# 3066H register map
File version: 1.0
Registers are 32-bit, access per field, reset 0x0 unless marked. A register's access mark holds for its fields unless they carry their own. Offsets are from the block's base; [hi:lo] are bit positions; {n}, {i} and the like mark numbered series.

## DMA0 — DMA0 peripheral interface
Base 0x1C000000
Same registers: DMA1 0x1C001000
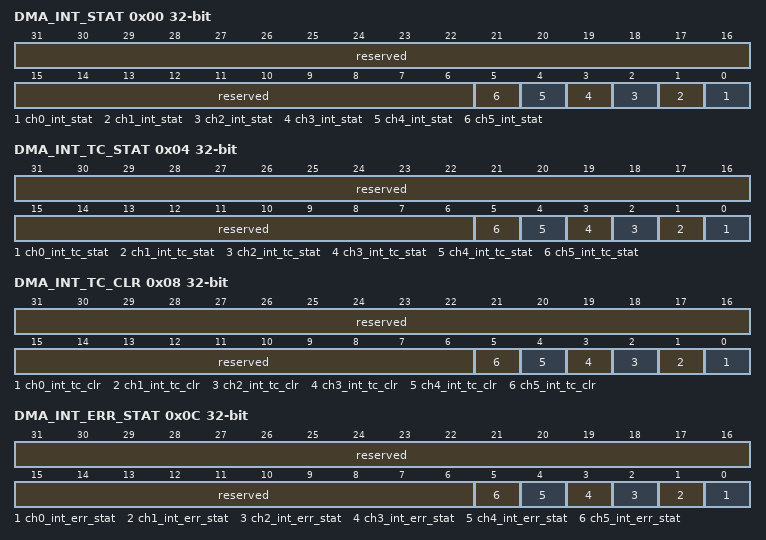
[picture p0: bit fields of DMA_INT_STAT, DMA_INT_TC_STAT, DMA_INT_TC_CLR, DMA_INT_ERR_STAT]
0x00 DMA_INT_STAT ro — DMA_INT_STAT为DMA中断状态寄存器。
  [31:6] reserved — 保留。
  [n] ch{n}_int_stat (n=0..5) — 通道{n}经屏蔽后的中断状态。 0：未产生中断； 1：已产生中断（传输错误或传输完成）。
0x04 DMA_INT_TC_STAT ro — DMA_INT_TC_STAT为DMA传输完成中断状态寄存器。
  [31:6] reserved — 保留。
  [n] ch{n}_int_tc_stat (n=0..5) — 通道{n}经屏蔽后的传输完成中断状态。 0：未产生中断； 1：已产生中断。
0x08 DMA_INT_TC_CLR — DMA_INT_TC_CLR为DMA传输完成中断清除寄存器。
  [31:6] reserved ro — 保留。
  [n] ch{n}_int_tc_clr wo (n=0..5) — 清除通道{n}传输完成中断。 0：不清除； 1：清除。
0x0C DMA_INT_ERR_STAT ro — DMA_INT_ERR_STAT为DMA错误中断状态寄存器。
  [31:6] reserved — 保留。
  [n] ch{n}_int_err_stat (n=0..5) — 通道{n}经屏蔽后的错误中断状态。 0：未产生中断； 1：已产生中断。
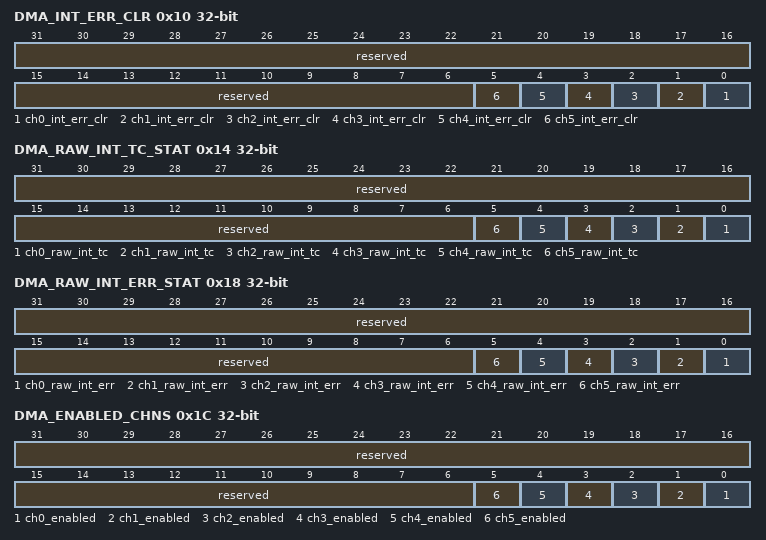
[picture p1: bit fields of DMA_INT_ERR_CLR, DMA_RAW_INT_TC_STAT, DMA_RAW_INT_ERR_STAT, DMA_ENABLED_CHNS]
0x10 DMA_INT_ERR_CLR — DMA_INT_ERR_CLR为DMA错误中断清除寄存器。
  [31:6] reserved ro — 保留。
  [n] ch{n}_int_err_clr wo (n=0..5) — 清除通道{n}错误中断。 0：不清除； 1：清除。
0x14 DMA_RAW_INT_TC_STAT ro — DMA_RAW_INT_TC_STAT为DMA原始传输完成中断寄存器。
  [31:6] reserved — 保留。
  [n] ch{n}_raw_int_tc (n=0..5) — 通道{n}原始传输完成中断状态。 0：未产生传输完成中断； 1：产生传输完成中断。
0x18 DMA_RAW_INT_ERR_STAT ro — DMA_RAW_INT_ERR_STAT为DMA原始错误中断寄存器。
  [31:6] reserved — 保留。
  [n] ch{n}_raw_int_err (n=0..5) — 通道{n}原始错误中断状态。 0：未产生错误中断； 1：产生错误中断。
0x1C DMA_ENABLED_CHNS ro — DMA_ENABLED_CHNS为DMA通道使能状态寄存器。
  [31:6] reserved — 保留。
  [n] ch{n}_enabled (n=0..5) — 通道{n}使能状态。 0：禁止； 1：使能。
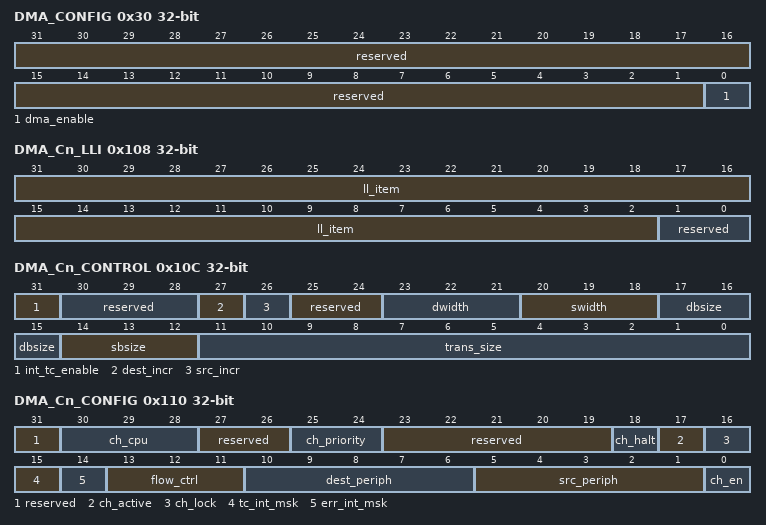
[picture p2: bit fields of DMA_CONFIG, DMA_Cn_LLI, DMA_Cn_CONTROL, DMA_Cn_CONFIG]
0x30 DMA_CONFIG — DMA_CONFIG为DMA配置寄存器。
  [31:1] reserved ro — 保留。
  [0] dma_enable rw — DMA控制器使能。 0：禁止DMA控制器； 1：使能DMA控制器。
0x34 DMA_SYNC rw — DMA_SYNC为DMA请求线同步使能寄存器。
  [31:0] dma_sync_disable — 控制是否需要对请求线进行同步，每bit对应请求请参见“11.3.2.2 外设请求线（SREQ、BREQ和外设流控请求线）”章节。 0：使能对应外设的DMA请求信号同步逻辑； 1：禁止对应外设的DMA请求信号同步逻辑。
0x100 DMA_Cn_SRC_ADDR rw — DMA_Cn_SRC_ADDR为DMA通道n（n=0，1，2，3，4，5）源地址寄存器。寄存器的偏移地址为0x100+n*0x20。其中n的取值为0～5，分别对应DMA通道0～5。每个寄存器在对应的通道被启动前都要由软件对其直接编程。当通道被启动后，该寄存器在下列情况下更新：当源地址递增时。当传完一个完整的数据块后，从链表节点中载入时。当该通道处于活动状态时，读该寄存器得不到有效信息。这是因为当软件得到读出的寄存器值，该寄存器的值已经随着通道传输改变了。对该寄存器的读操作一般是用在通道停止传输的时候，此时读取值显示的是DMA读最后一项时的源地址。
  [31:0] src_addr — DMA源地址。
0x104 DMA_Cn_DEST_ADDR rw — DMA_Cn_DEST_ADDR为DMA通道n（n=0，1，2，3，4，5）目的地址寄存器。偏移地址为：0x104+n*0x20。其中，n的取值为0～5，分别对应DMA通道0～5。通道目的地址寄存器DMA_Cn_DEST_ADDR包含了当前待传数据的目的地址。每个寄存器在对应的通道被启动前，都要由软件对其直接编程。当通道被启动后，该寄存器在下列情况下更新：目的地址递增。传完一个完整的数据块后，从链表节点中载入。当该通道处于活动状态时，读该寄存器得不到有效信息。这是因为当软件得到读出的寄存器值，该寄存器的值已经随着通道传输改变了。在通道停止传输时，读该寄存器，此时读取值显示的是DMA写最后一项时的目的地址。
  [31:0] dest_addr — DMA目的地址。
0x108 DMA_Cn_LLI — DMA_Cn_LLI为DMA通道n（n=0，1，2，3，4，5）链表信息寄存器。偏移地址为：0x108。其中，n的取值为0～5，分别对应DMA通道0～DMA通道5。详细内容请参见“11.3.4 DMA链表”章节。
  [31:2] ll_item rw — 下一个链表节点地址的[31:2]位，地址位[1:0]为0。要求链表地址4Byte对齐。
  [1:0] reserved ro — 保留，写入时必须写0，读出时应屏蔽该位。
0x10C DMA_Cn_CONTROL — DMA_Cn_CONTROL为DMA通道n（n=0，1，2，3，4，5）控制寄存器。偏移地址为：0x10C。其中，n的取值为0～5，分别对应DMA通道0～DMA通道5。
  [31] int_tc_enable rw — 传输完成中断使能位。该位用于决定当前链表节点是否触发传输完成中断。 0：当前链表节点不触发传输完成中断； 1：当前链表节点触发传输完成中断。
  [30:28] reserved ro — 保留。
  [27] dest_incr rw — 目的地址递增。 0：目的地址不递增； 1：目的地址每传一个数就递增一次。 目的设备为外设时目的地址不递增；目的设备为存储器时目的地址递增。
  [26] src_incr rw — 源地址递增。 0：源地址不递增； 1：源地址每传一个数就递增一次。 源设备为外设时源地址不递增；源设备为存储器时源地址递增。
  [25:24] reserved ro — 保留。
  [23:21] dwidth rw — 目的设备传输位宽。 宽于Master位宽的传输位宽是非法的。 目的设备和源设备的位宽可以不一样，硬件自动对数据进行pack和unpack。 dwidth的值和具体的位宽对应关系如表11-5所示。
  [20:18] swidth rw — 源设备传输位宽。 宽于Master位宽的传输位宽是非法的。 目的设备和源设备的位宽可以不一样，硬件自动对数据进行pack和unpack。 swidth的值和具体的位宽对应关系如表11-5所示。
  [17:15] dbsize rw — 目的设备burst长度。 表示目的设备请求1次burst传输（BREQ），DMA向目的地址（固定或递增地址）写数据的个数。 若目的设备是外设，内部有FIFO，burst长度不能超过其FIFO深度，建议配合FIFO水线使用。 若目的设备是外设，内部无FIFO，若配置了目的地址递增，则burst长度不能超过外设的地址空间。否则，递增的目的地址会超过该设备的地址空间，若该地址无映射，那么可能导致无法预料的结果。 若目的设备是存储器，若配置了目的地址递增，则burst长度的配置需要考虑存储器地址边界。目的地址+burst长度不能超过其存储器地址边界。否则，目的地址递增会访问到超过该设备的地址空间，若该地址无映射，那么可能导致无法预料的结果。 若目的设备只支持BREQ，不支持SREQ。目前设备dbsize的配置有限制。目的设备dbsize * dwidth的整数倍须等于trans_size * swidth。 dbsize的值和具体的传输长度的对应关系如表11-4所示。
  [14:12] sbsize rw — 源设备burst长度。 表示源设备请求1次burst传输（BREQ），DMA从源地址（固定或递增地址）读数据的个数。 若源设备是外设，内部有FIFO，burst长度不能超过其FIFO深度，建议配合FIFO水线使用。 若源设备是外设，内部无FIFO，若配置了源地址递增，则burst长度不能超过外设的地址空间。否则，递增的源地址会超过该设备的地址空间，若该地址无映射，那么可能导致无法预料的结果。 若源设备是存储器，若配置了源地址递增，则burst长度的配置需要考虑存储器地址边界。源地址+burst长度不能超过其存储器地址边界。否则，源地址递增会访问到超过该设备的地址空间，若该地址无映射，那么可能导致无法预料的结果。 若源设备只支持BREQ，不支持SREQ。源设备sbsize的配置有限制。源设备sbsize * swidth的整数倍须等于trans_size * swidth。 sbsize的值和具体的传输长度的对应关系如表11-4所示。
  [11:0] trans_size rw — 通过写该寄存器可设定DMA传输个数，前提是DMA是流控制器。这里transfer size表示的源设备待传数据的个数。 读该寄存器可得到在与目的设备相连的总线上已传出的数据个数。 当该通道处于活动状态时，读该寄存器得不到有效信息。这是因为当软件得到读出的寄存器值，该寄存器的值已经随着通道传输改变了。对该寄存器的读操作一般是用在通道被启动后然后又停止传输时。
0x110 DMA_Cn_CONFIG — DMA_Cn_CONFIG为DMA通道n（n=0，1，2，3，4，5）配置寄存器。偏移地址为：0x110。其中，n的取值为0～5，分别对应DMA通道0～DMA通道5。该寄存器在新的链表节点被载入时不会被更新。
  [31] reserved ro — 保留。
  [30:28] ch_cpu rw — 配置该通道的CPU属性。 bit[30]：该通道属于CPU2。 bit[29]：该通道属于CPU1。 bit[28]：该通道属于CPU0。 对应bit位为1，代表中断上报到对应的CPU。
  [27:26] reserved ro — 保留。
  [25:24] ch_priority rw — 通道优先级。相同优先级的通道，序号低的优先。须在使能通道前配置，一旦通道被使能且未完成传输，禁止修改通道优先级，否则可能导致数据丢失。 00：低优先； 01：中优先； 10：高优先； 11：最高优先。
  [23:19] reserved ro — 保留。
  [18] ch_halt rw — Halt位。 0：允许DMA请求； 1：忽略后来的DMA请求，通道FIFO中的内容都被传完。 该位可以和Active位以及通道使能位一起用于无数据丢失地关闭一个DMA通道。
  [17] ch_active ro — Active位。 0：通道FIFO中没有数据； 1：通道FIFO中有数据。 该位可以和Halt位以及通道使能位一起用于无数据丢失地关闭一个DMA通道。
  [16] ch_lock rw — Lock位。 0：禁止总线上lock传输； 1：使能总线上lock传输。
  [15] tc_int_msk rw — 传输完成中断屏蔽位。 0：屏蔽本通道的传输完成中断。 1：不屏蔽本通道的传输完成中断。
  [14] err_int_msk rw — 错误中断屏蔽位。 0：屏蔽本通道的错误中断。 1：不屏蔽本通道的错误中断。
  [13:11] flow_ctrl rw — 流控及传输类型字段。 该字段用于指定流控制器和传输类型。流控制器可以是DMA、源设备和目的设备。 传输类型可以是存储器到外设、外设到存储器、外设到外设、存储器到存储器。详细描述如表11-6所示。
  [10:6] dest_periph rw — 目的设备。该字段用于选择一个外设请求信号作为本通道的DMA目的设备的请求信号。 如果DMA传输的目的设备是存储器则该字段被忽略。
  [5:1] src_periph rw — 源设备。该字段用于选择一个外设请求信号作为本通道的DMA源设备的请求信号。 如果DMA传输的源设备是存储器则该字段被忽略。
  [0] ch_en rw — 通道使能位。读该寄存器可得知本通道当前是处于什么状态（也可通过读寄存器DMA_ENABLED_CHNS得到）。 0：关闭通道； 1：启动通道。 通过清零可关闭通道。将该位被清零时，当前的总线传输会继续执行直到完成。然后通道关闭，FIFO中剩余的数据全部丢失；当最后一个LLI完成或传输中出现错误时，通道也会被关闭，同时该位被清零；如果要关闭通道，而又不使通道FIFO中的数据丢失，则Halt位也必须同时被置位，使通道忽略后来的DMA请求。然后必须轮询active位，直到其值变为0，表明通道FIFO中不再留有数据。此时才能够清除enable位。 通过置位启动通道必须先重新初始化通道，然后才能再次启动通道；若通过简单的置位启动通道，会引发不可预测性的后果。 当刚通过写DMA_Cn_CONFIG bit[0]位关闭一个通道时，必须要等到轮询到寄存器DMA_ENABLED_CHNS中的相应bit为0后，才能将DMA_Cn_CONFIG bit[0]重新置位。这是因为通道实际的关闭并没有在将DMA_Cn_CONFIG bit[0]清零后立即生效。总线burst的运行时延时也必须要考虑到。
